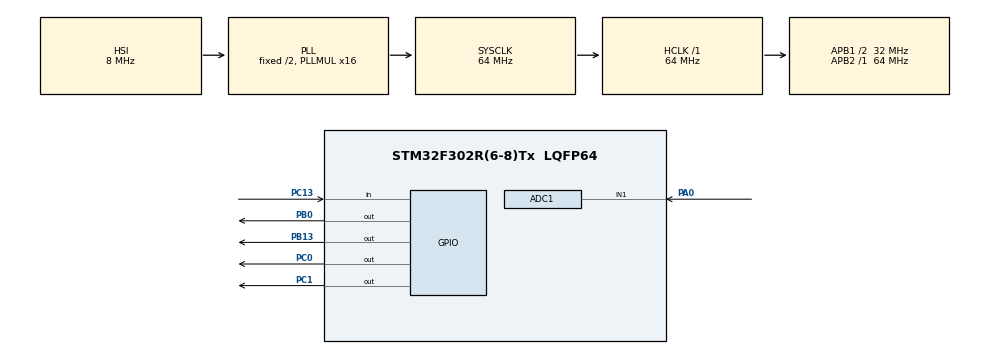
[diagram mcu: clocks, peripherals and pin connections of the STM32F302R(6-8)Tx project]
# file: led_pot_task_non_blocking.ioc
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ADC1.Channel-0\#ChannelRegularConversion=ADC_CHANNEL_1
ADC1.NbrOfConversionFlag=1
ADC1.Offset-0\#ChannelRegularConversion=0
ADC1.OffsetNumber-0\#ChannelRegularConversion=ADC_OFFSET_NONE
ADC1.Rank-0\#ChannelRegularConversion=1
ADC1.SamplingTime-0\#ChannelRegularConversion=ADC_SAMPLETIME_601CYCLES_5
ADC1.master=1
FREERTOS.Tasks01=normal_led,0,128,Start_normal_led,Default,NULL,Dynamic,NULL,NULL;high_led,2,128,Start_high_led,Default,NULL,Dynamic,NULL,NULL;low_led,-2,128,Start_low_led,Default,NULL,Dynamic,NULL,NULL;adc,2,128,StartTask04,Default,NULL,Dynamic,NULL,NULL
FREERTOS.configUSE_NEWLIB_REENTRANT=1
Mcu.Family=STM32F3
Mcu.Name=STM32F302R(6-8)Tx
Mcu.Package=LQFP64
NVIC.PriorityGroup=NVIC_PRIORITYGROUP_4
NVIC.TIM1_UP_TIM16_IRQn=true\:15\:0\:false\:false\:true\:false\:false\:true\:true
NVIC.TimeBase=TIM1_UP_TIM16_IRQn
NVIC.TimeBaseIP=TIM1
PA0.Mode=IN1-Single-Ended
PA0.Signal=ADC1_IN1
PA13.Mode=Serial_Wire
PA13.Signal=SYS_JTMS-SWDIO
PA14.Mode=Serial_Wire
PA14.Signal=SYS_JTCK-SWCLK
PB0.Signal=GPIO_Output
PB13.Signal=GPIO_Output
PC0.Signal=GPIO_Output
PC1.Signal=GPIO_Output
PC13.Signal=GPIO_Input
PF0-OSC_IN.Mode=HSE-External-Oscillator
PF0-OSC_IN.Signal=RCC_OSC_IN
PF1-OSC_OUT.Mode=HSE-External-Oscillator
PF1-OSC_OUT.Signal=RCC_OSC_OUT
ProjectManager.HeapSize=0x200
ProjectManager.StackSize=0x400
ProjectManager.TargetToolchain=STM32CubeIDE
RCC.AHBFreq_Value=64000000
RCC.APB1CLKDivider=RCC_HCLK_DIV2
RCC.APB1Freq_Value=32000000
RCC.APB1TimFreq_Value=64000000
RCC.APB2Freq_Value=64000000
RCC.APB2TimFreq_Value=64000000
RCC.CortexFreq_Value=64000000
RCC.HCLKFreq_Value=64000000
RCC.HSE_VALUE=8000000
RCC.HSI_VALUE=8000000
RCC.PLLM=8
RCC.PLLMUL=RCC_PLL_MUL16
RCC.PLLN=336
RCC.PLLP=RCC_PLLP_DIV4
RCC.PLLQ=7
RCC.RCC_PLLsource_Clock_Source_FROM_HSE=RCC_HSE_PREDIV_DIV2
RCC.SYSCLKFreq_VALUE=64000000
RCC.SYSCLKSourceVirtual=RCC_SYSCLKSOURCE_PLLCLK
RCC.USBFreq_Value=64000000
VP_FREERTOS_VS_CMSIS_V1.Mode=CMSIS_V1
VP_SYS_VS_tim1.Mode=TIM1
board=NUCLEO-F302R8

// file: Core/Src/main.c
/* USER CODE BEGIN Header */
/**
  ******************************************************************************
  * @file           : main.c
  * @brief          : Main program body
  ******************************************************************************
  * @attention
  *
  * Copyright (c) 2024 STMicroelectronics.
  * All rights reserved.
  *
  * This software is licensed under terms that can be found in the LICENSE file
  * in the root directory of this software component.
  * If no LICENSE file comes with this software, it is provided AS-IS.
  *
  ******************************************************************************
  */
/* USER CODE END Header */
#include "main.h"
#include "cmsis_os.h"

/* USER CODE BEGIN PM */
uint32_t adc_value=0;
/* USER CODE END PM */

ADC_HandleTypeDef hadc1;

osThreadId normal_ledHandle;
osThreadId high_ledHandle;
osThreadId low_ledHandle;
osThreadId adcHandle;

void SystemClock_Config(void);
static void MX_GPIO_Init(void);
static void MX_ADC1_Init(void);
void Start_normal_led(void const * argument);
void Start_high_led(void const * argument);
void Start_low_led(void const * argument);
void StartTask04(void const * argument);

int main(void)
{

  /* MCU Configuration--------------------------------------------------------*/

  /* Reset of all peripherals, Initializes the Flash interface and the Systick. */
  HAL_Init();

  /* Configure the system clock */
  SystemClock_Config();

  /* Initialize all configured peripherals */
  MX_GPIO_Init();
  MX_ADC1_Init();

  /* Create the thread(s) */
  /* definition and creation of normal_led */
  osThreadDef(normal_led, Start_normal_led, osPriorityNormal, 0, 128);
  normal_ledHandle = osThreadCreate(osThread(normal_led), NULL);

  /* definition and creation of high_led */
  osThreadDef(high_led, Start_high_led, osPriorityHigh, 0, 128);
  high_ledHandle = osThreadCreate(osThread(high_led), NULL);

  /* definition and creation of low_led */
  osThreadDef(low_led, Start_low_led, osPriorityLow, 0, 128);
  low_ledHandle = osThreadCreate(osThread(low_led), NULL);

  /* definition and creation of adc */
  osThreadDef(adc, StartTask04, osPriorityHigh, 0, 128);
  adcHandle = osThreadCreate(osThread(adc), NULL);

  /* Start scheduler */
  osKernelStart();

  /* We should never get here as control is now taken by the scheduler */

  /* Infinite loop */
  while (1)
  {

  }
}

void SystemClock_Config(void)
{
  RCC_OscInitTypeDef RCC_OscInitStruct = {0};
  RCC_ClkInitTypeDef RCC_ClkInitStruct = {0};
  RCC_PeriphCLKInitTypeDef PeriphClkInit = {0};

  /** Initializes the RCC Oscillators according to the specified parameters
  * in the RCC_OscInitTypeDef structure.
  */
  RCC_OscInitStruct.OscillatorType = RCC_OSCILLATORTYPE_HSI;
  RCC_OscInitStruct.HSIState = RCC_HSI_ON;
  RCC_OscInitStruct.HSICalibrationValue = RCC_HSICALIBRATION_DEFAULT;
  RCC_OscInitStruct.PLL.PLLState = RCC_PLL_ON;
  RCC_OscInitStruct.PLL.PLLSource = RCC_PLLSOURCE_HSI;
  RCC_OscInitStruct.PLL.PLLMUL = RCC_PLL_MUL16;
  if (HAL_RCC_OscConfig(&RCC_OscInitStruct) != HAL_OK)
  {
    Error_Handler();
  }

  /** Initializes the CPU, AHB and APB buses clocks
  */
  RCC_ClkInitStruct.ClockType = RCC_CLOCKTYPE_HCLK|RCC_CLOCKTYPE_SYSCLK
                              |RCC_CLOCKTYPE_PCLK1|RCC_CLOCKTYPE_PCLK2;
  RCC_ClkInitStruct.SYSCLKSource = RCC_SYSCLKSOURCE_PLLCLK;
  RCC_ClkInitStruct.AHBCLKDivider = RCC_SYSCLK_DIV1;
  RCC_ClkInitStruct.APB1CLKDivider = RCC_HCLK_DIV2;
  RCC_ClkInitStruct.APB2CLKDivider = RCC_HCLK_DIV1;

  if (HAL_RCC_ClockConfig(&RCC_ClkInitStruct, FLASH_LATENCY_2) != HAL_OK)
  {
    Error_Handler();
  }
  PeriphClkInit.PeriphClockSelection = RCC_PERIPHCLK_ADC1;
  PeriphClkInit.Adc1ClockSelection = RCC_ADC1PLLCLK_DIV1;

  if (HAL_RCCEx_PeriphCLKConfig(&PeriphClkInit) != HAL_OK)
  {
    Error_Handler();
  }
}

static void MX_ADC1_Init(void)
{

  ADC_ChannelConfTypeDef sConfig = {0};

  /** Common config
  */
  hadc1.Instance = ADC1;
  hadc1.Init.ClockPrescaler = ADC_CLOCK_ASYNC_DIV1;
  hadc1.Init.Resolution = ADC_RESOLUTION_12B;
  hadc1.Init.ScanConvMode = ADC_SCAN_DISABLE;
  hadc1.Init.ContinuousConvMode = DISABLE;
  hadc1.Init.DiscontinuousConvMode = DISABLE;
  hadc1.Init.ExternalTrigConvEdge = ADC_EXTERNALTRIGCONVEDGE_NONE;
  hadc1.Init.ExternalTrigConv = ADC_SOFTWARE_START;
  hadc1.Init.DataAlign = ADC_DATAALIGN_RIGHT;
  hadc1.Init.NbrOfConversion = 1;
  hadc1.Init.DMAContinuousRequests = DISABLE;
  hadc1.Init.EOCSelection = ADC_EOC_SINGLE_CONV;
  hadc1.Init.LowPowerAutoWait = DISABLE;
  hadc1.Init.Overrun = ADC_OVR_DATA_OVERWRITTEN;
  if (HAL_ADC_Init(&hadc1) != HAL_OK)
  {
    Error_Handler();
  }

  /** Configure Regular Channel
  */
  sConfig.Channel = ADC_CHANNEL_1;
  sConfig.Rank = ADC_REGULAR_RANK_1;
  sConfig.SingleDiff = ADC_SINGLE_ENDED;
  sConfig.SamplingTime = ADC_SAMPLETIME_601CYCLES_5;
  sConfig.OffsetNumber = ADC_OFFSET_NONE;
  sConfig.Offset = 0;
  if (HAL_ADC_ConfigChannel(&hadc1, &sConfig) != HAL_OK)
  {
    Error_Handler();
  }

}

static void MX_GPIO_Init(void)
{
  GPIO_InitTypeDef GPIO_InitStruct = {0};

  /* GPIO Ports Clock Enable */
  __HAL_RCC_GPIOC_CLK_ENABLE();
  __HAL_RCC_GPIOF_CLK_ENABLE();
  __HAL_RCC_GPIOA_CLK_ENABLE();
  __HAL_RCC_GPIOB_CLK_ENABLE();

  /*Configure GPIO pin Output Level */
  HAL_GPIO_WritePin(GPIOC, GPIO_PIN_0|GPIO_PIN_1, GPIO_PIN_RESET);

  /*Configure GPIO pin Output Level */
  HAL_GPIO_WritePin(GPIOB, GPIO_PIN_0|GPIO_PIN_13, GPIO_PIN_RESET);

  /*Configure GPIO pin : PC13 */
  GPIO_InitStruct.Pin = GPIO_PIN_13;
  GPIO_InitStruct.Mode = GPIO_MODE_INPUT;
  GPIO_InitStruct.Pull = GPIO_NOPULL;
  HAL_GPIO_Init(GPIOC, &GPIO_InitStruct);

  /*Configure GPIO pins : PC0 PC1 */
  GPIO_InitStruct.Pin = GPIO_PIN_0|GPIO_PIN_1;
  GPIO_InitStruct.Mode = GPIO_MODE_OUTPUT_PP;
  GPIO_InitStruct.Pull = GPIO_NOPULL;
  GPIO_InitStruct.Speed = GPIO_SPEED_FREQ_LOW;
  HAL_GPIO_Init(GPIOC, &GPIO_InitStruct);

  /*Configure GPIO pins : PB0 PB13 */
  GPIO_InitStruct.Pin = GPIO_PIN_0|GPIO_PIN_13;
  GPIO_InitStruct.Mode = GPIO_MODE_OUTPUT_PP;
  GPIO_InitStruct.Pull = GPIO_NOPULL;
  GPIO_InitStruct.Speed = GPIO_SPEED_FREQ_LOW;
  HAL_GPIO_Init(GPIOB, &GPIO_InitStruct);

}

void Start_normal_led(void const * argument)
{
  /* USER CODE BEGIN 5 */
  /* Infinite loop */
  for(;;)
  {
	  HAL_GPIO_TogglePin(GPIOC, GPIO_PIN_1);
    osDelay(200);
  }
  /* USER CODE END 5 */
}

void Start_high_led(void const * argument)
{
  /* USER CODE BEGIN Start_high_led */
  /* Infinite loop */
  for(;;)
  {
	  HAL_GPIO_TogglePin(GPIOB, GPIO_PIN_0);
    osDelay(200);
  }
  /* USER CODE END Start_high_led */
}

void Start_low_led(void const * argument)
{
  /* USER CODE BEGIN Start_low_led */
  /* Infinite loop */
  for(;;)
  {
	  HAL_GPIO_TogglePin(GPIOC, GPIO_PIN_0);
    osDelay(200);
  }
  /* USER CODE END Start_low_led */
}

void StartTask04(void const * argument)
{
  /* USER CODE BEGIN StartTask04 */
  /* Infinite loop */
  for(;;)
  {
	  HAL_ADC_Start(&hadc1);
	  HAL_ADC_PollForConversion(&hadc1, HAL_MAX_DELAY);
	  adc_value=HAL_ADC_GetValue(&hadc1);
    osDelay(10);
  }
  /* USER CODE END StartTask04 */
}

void HAL_TIM_PeriodElapsedCallback(TIM_HandleTypeDef *htim)
{
  if (htim->Instance == TIM1) {
    HAL_IncTick();
  }
}

void Error_Handler(void)
{
  __disable_irq();
  while (1)
  {
  }
}
